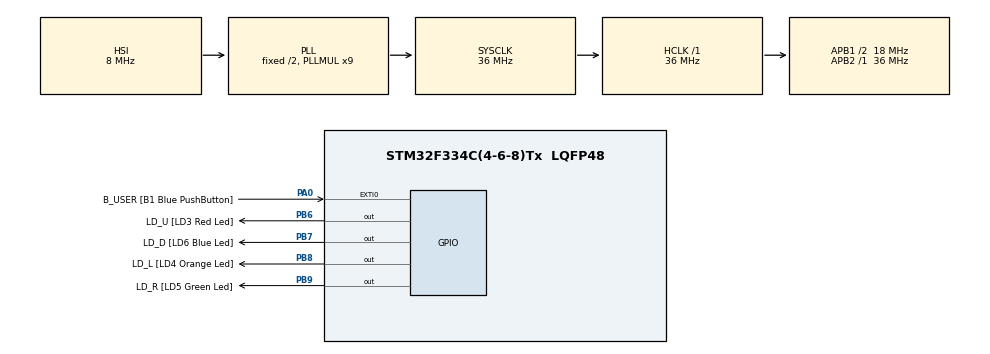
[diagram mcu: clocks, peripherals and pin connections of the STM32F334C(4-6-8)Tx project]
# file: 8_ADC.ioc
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ADC1.Channel-4\#ChannelRegularConversion=ADC_CHANNEL_VREFINT
ADC1.NbrOfConversionFlag=1
ADC1.Offset-4\#ChannelRegularConversion=0
ADC1.OffsetNumber-4\#ChannelRegularConversion=ADC_OFFSET_NONE
ADC1.Rank-4\#ChannelRegularConversion=1
ADC1.SamplingTime-4\#ChannelRegularConversion=ADC_SAMPLETIME_1CYCLE_5
ADC1.master=1
Mcu.Family=STM32F3
Mcu.Name=STM32F334C(4-6-8)Tx
Mcu.Package=LQFP48
NVIC.ADC1_2_IRQn=true\:0\:0\:false\:false\:true\:true
NVIC.PriorityGroup=NVIC_PRIORITYGROUP_0
PA0.GPIO_Label=B_USER [B1 Blue PushButton]
PA0.GPIO_ModeDefaultEXTI=GPIO_MODE_EVT_RISING
PA0.Signal=GPXTI0
PA1.GPIO_Label=Vin_Sense [Buck/Boost Converter]
PA1.Signal=ADC1_IN2
PA10.GPIO_Label=N2_Drive [Buck/Boost Converter]
PA10.Signal=HRTIM1_CHB1
PA11.GPIO_Label=P2_Drive [Buck/Boost Converter]
PA11.Signal=HRTIM1_CHB2
PA13.GPIO_Label=SWDIO
PA13.Signal=SYS_JTMS-SWDIO
PA14.GPIO_Label=SWCLK
PA14.Signal=SYS_JTCK-SWCLK
PA3.GPIO_Label=Vout_Sense [Buck/Boost Converter]
PA3.Signal=ADC1_IN4
PA8.GPIO_Label=P1_Drive [Buck/Boost Converter]
PA8.Signal=HRTIM1_CHA1
PA9.GPIO_Label=N1_Drive [Buck/Boost Converter]
PA9.Signal=HRTIM1_CHA2
PB0.GPIO_Label=BK_Sense [Led Buck Converter]
PB0.Signal=ADC1_IN11
PB12.GPIO_Label=BK_Drive [Led Buck Converter]
PB12.Signal=HRTIM1_CHC1
PB14.GPIO_Label=RC [Buck/Boost Converter]
PB14.Signal=HRTIM1_CHD1
PB6.GPIO_Label=LD_U [LD3 Red Led]
PB6.Signal=GPIO_Output
PB7.GPIO_Label=LD_D [LD6 Blue Led]
PB7.Signal=GPIO_Output
PB8.GPIO_Label=LD_L [LD4 Orange Led]
PB8.Signal=GPIO_Output
PB9.GPIO_Label=LD_R [LD5 Green Led]
PB9.Signal=GPIO_Output
PF0\ /\ OSC_IN.GPIO_Label=PF0-OSC_IN
PF0\ /\ OSC_IN.Signal=RCC_OSC_IN
PF1\ /\ OSC_OUT.GPIO_Label=PF1_OSC_OUT
PF1\ /\ OSC_OUT.Signal=RCC_OSC_OUT
ProjectManager.HeapSize=0x200
ProjectManager.StackSize=0x400
ProjectManager.TargetToolchain=SW4STM32
RCC.AHBFreq_Value=36000000
RCC.APB1CLKDivider=RCC_HCLK_DIV2
RCC.APB1Freq_Value=18000000
RCC.APB1TimFreq_Value=36000000
RCC.APB2Freq_Value=36000000
RCC.APB2TimFreq_Value=36000000
RCC.CortexFreq_Value=36000000
RCC.HCLKFreq_Value=36000000
RCC.HSE_VALUE=8000000
RCC.HSI_VALUE=8000000
RCC.LSE_VALUE=32768
RCC.PLLMUL=RCC_PLL_MUL9
RCC.SYSCLKFreq_VALUE=36000000
RCC.SYSCLKSourceVirtual=RCC_SYSCLKSOURCE_PLLCLK
VP_ADC1_Vref_Input.Mode=IN-Vrefint
board=STM32F3348-DISCO

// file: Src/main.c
/**
  ******************************************************************************
  * File Name          : main.c
  * Description        : Main program body
  ******************************************************************************
  ** This notice applies to any and all portions of this file
  * that are not between comment pairs USER CODE BEGIN and
  * USER CODE END. Other portions of this file, whether
  * inserted by the user or by software development tools
  * are owned by their respective copyright owners.
  *
  * COPYRIGHT(c) 2017 STMicroelectronics
  *
  * Redistribution and use in source and binary forms, with or without modification,
  * are permitted provided that the following conditions are met:
  *   1. Redistributions of source code must retain the above copyright notice,
  *      this list of conditions and the following disclaimer.
  *   2. Redistributions in binary form must reproduce the above copyright notice,
  *      this list of conditions and the following disclaimer in the documentation
  *      and/or other materials provided with the distribution.
  *   3. Neither the name of STMicroelectronics nor the names of its contributors
  *      may be used to endorse or promote products derived from this software
  *      without specific prior written permission.
  *
  * THIS SOFTWARE IS PROVIDED BY THE COPYRIGHT HOLDERS AND CONTRIBUTORS "AS IS"
  * AND ANY EXPRESS OR IMPLIED WARRANTIES, INCLUDING, BUT NOT LIMITED TO, THE
  * IMPLIED WARRANTIES OF MERCHANTABILITY AND FITNESS FOR A PARTICULAR PURPOSE ARE
  * DISCLAIMED. IN NO EVENT SHALL THE COPYRIGHT HOLDER OR CONTRIBUTORS BE LIABLE
  * FOR ANY DIRECT, INDIRECT, INCIDENTAL, SPECIAL, EXEMPLARY, OR CONSEQUENTIAL
  * DAMAGES (INCLUDING, BUT NOT LIMITED TO, PROCUREMENT OF SUBSTITUTE GOODS OR
  * SERVICES; LOSS OF USE, DATA, OR PROFITS; OR BUSINESS INTERRUPTION) HOWEVER
  * CAUSED AND ON ANY THEORY OF LIABILITY, WHETHER IN CONTRACT, STRICT LIABILITY,
  * OR TORT (INCLUDING NEGLIGENCE OR OTHERWISE) ARISING IN ANY WAY OUT OF THE USE
  * OF THIS SOFTWARE, EVEN IF ADVISED OF THE POSSIBILITY OF SUCH DAMAGE.
  *
  ******************************************************************************
  */

#include "main.h"
#include "stm32f3xx_hal.h"
#include "adc.h"
#include "gpio.h"

/* USER CODE BEGIN PV */
/* Private variables ---------------------------------------------------------*/

/* USER CODE END PV */

void SystemClock_Config(void);

/* USER CODE BEGIN PFP */
/* Private function prototypes -----------------------------------------------*/

/* USER CODE END PFP */

int main(void)
{

  /* MCU Configuration----------------------------------------------------------*/

  /* Reset of all peripherals, Initializes the Flash interface and the Systick. */
  HAL_Init();

  /* Configure the system clock */
  SystemClock_Config();

  /* Initialize all configured peripherals */
  MX_GPIO_Init();
  MX_ADC1_Init();

  /* USER CODE BEGIN 2 */

  HAL_ADC_Start_IT(&hadc1);
  /* USER CODE END 2 */

  /* Infinite loop */
  while (1)
  {

	  HAL_Delay(200);
	  HAL_ADC_Start_IT(&hadc1);
  }

}

/** System Clock Configuration
*/
void SystemClock_Config(void)
{

  RCC_OscInitTypeDef RCC_OscInitStruct;
  RCC_ClkInitTypeDef RCC_ClkInitStruct;
  RCC_PeriphCLKInitTypeDef PeriphClkInit;

    /**Initializes the CPU, AHB and APB busses clocks
    */
  RCC_OscInitStruct.OscillatorType = RCC_OSCILLATORTYPE_HSI;
  RCC_OscInitStruct.HSIState = RCC_HSI_ON;
  RCC_OscInitStruct.HSICalibrationValue = 16;
  RCC_OscInitStruct.PLL.PLLState = RCC_PLL_ON;
  RCC_OscInitStruct.PLL.PLLSource = RCC_PLLSOURCE_HSI;
  RCC_OscInitStruct.PLL.PLLMUL = RCC_PLL_MUL9;
  if (HAL_RCC_OscConfig(&RCC_OscInitStruct) != HAL_OK)
  {
    _Error_Handler(__FILE__, __LINE__);
  }

    /**Initializes the CPU, AHB and APB busses clocks
    */
  RCC_ClkInitStruct.ClockType = RCC_CLOCKTYPE_HCLK|RCC_CLOCKTYPE_SYSCLK
                              |RCC_CLOCKTYPE_PCLK1|RCC_CLOCKTYPE_PCLK2;
  RCC_ClkInitStruct.SYSCLKSource = RCC_SYSCLKSOURCE_PLLCLK;
  RCC_ClkInitStruct.AHBCLKDivider = RCC_SYSCLK_DIV1;
  RCC_ClkInitStruct.APB1CLKDivider = RCC_HCLK_DIV2;
  RCC_ClkInitStruct.APB2CLKDivider = RCC_HCLK_DIV1;

  if (HAL_RCC_ClockConfig(&RCC_ClkInitStruct, FLASH_LATENCY_1) != HAL_OK)
  {
    _Error_Handler(__FILE__, __LINE__);
  }

  PeriphClkInit.PeriphClockSelection = RCC_PERIPHCLK_ADC12;
  PeriphClkInit.Adc12ClockSelection = RCC_ADC12PLLCLK_DIV1;
  if (HAL_RCCEx_PeriphCLKConfig(&PeriphClkInit) != HAL_OK)
  {
    _Error_Handler(__FILE__, __LINE__);
  }

    /**Configure the Systick interrupt time
    */
  HAL_SYSTICK_Config(HAL_RCC_GetHCLKFreq()/1000);

    /**Configure the Systick
    */
  HAL_SYSTICK_CLKSourceConfig(SYSTICK_CLKSOURCE_HCLK);

  /* SysTick_IRQn interrupt configuration */
  HAL_NVIC_SetPriority(SysTick_IRQn, 0, 0);
}

void _Error_Handler(char * file, int line)
{
  while(1)
  {
  }
}

/************************ (C) COPYRIGHT STMicroelectronics *****END OF FILE****/
